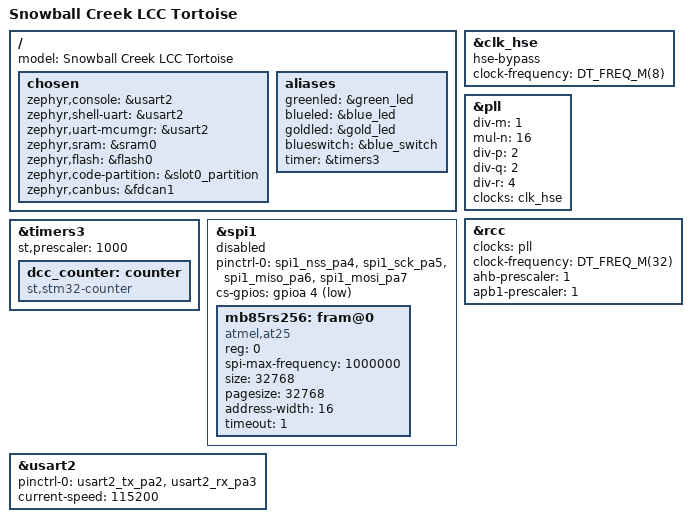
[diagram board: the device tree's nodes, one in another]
/dts-v1/;
#include <st/g0/stm32g0b1Xb.dtsi>
#include <st/g0/stm32g0b1c(b-c-e)tx-pinctrl.dtsi>

#include <zephyr/dt-bindings/input/input-event-codes.h>
#include <zephyr/dt-bindings/pinctrl/stm32-pinctrl.h>
#include <zephyr/dt-bindings/pinctrl/stm32-pinctrl-common.h>

/ {
	model = "Snowball Creek LCC Tortoise";

	chosen {
		zephyr,console = &usart2;
		zephyr,shell-uart = &usart2;
		zephyr,uart-mcumgr = &usart2;
		zephyr,sram = &sram0;
		zephyr,flash = &flash0;
		zephyr,code-partition = &slot0_partition;
		zephyr,canbus = &fdcan1;
	};


	aliases {
		greenled = &green_led;
		blueled = &blue_led;
		goldled = &gold_led;
		blueswitch = &blue_switch;
		timer = &timers3;
	};
};

/*
&clk_lsi {
	status = "okay";
};

&clk_hsi {
	status = "okay";
};

&clk_hsi48 {
	status = "okay";
	crs-usb-sof;
};
*/

&clk_hse {
	status = "okay";
	hse-bypass;
	clock-frequency = <DT_FREQ_M(8)>;
};

&pll {
	div-m = <1>;
	mul-n = <16>;
	div-p = <2>;
	div-q = <2>;
	div-r = <4>;
	clocks = <&clk_hse>;
	status = "okay";
};


&rcc {
	clocks = <&pll>;
	clock-frequency = <DT_FREQ_M(32)>;
	ahb-prescaler = <1>;
	apb1-prescaler = <1>;
};


/*
zephyr_udc0: &usb {
	pinctrl-0 = <&usb_dm_pa11 &usb_dp_pa12>;
	pinctrl-names = "default";
	status = "okay";
};
*/

/*
&usart1 {
	pinctrl-0 = <&usart1_tx_pc4 &usart1_rx_pc5>;
	pinctrl-names = "default";
	current-speed = <115200>;
	status = "disabled";
};
*/


/*
&rtc {
	clocks = <&rcc STM32_CLOCK_BUS_APB1 0x00000400>,
		 <&rcc STM32_SRC_LSI RTC_SEL(2)>;
	status = "okay";
};

&iwdg {
	status = "okay";
};
*/

&timers3 {
	st,prescaler = <1000>;
	status = "okay";
	dcc_counter: counter {
		compatible = "st,stm32-counter";
		status = "okay";
	};
};

/*
&timers15 {
	st,prescaler = <10000>;
	status = "okay";
	pwm15: pwm {
		status = "okay";
		pinctrl-0 = <&tim15_ch1_pb14>;
		pinctrl-names = "default";
	};
};

&i2c1 {
	pinctrl-0 = <&i2c1_scl_pb8 &i2c1_sda_pb9>;
	pinctrl-names = "default";
	status = "okay";
	clock-frequency = <I2C_BITRATE_FAST>;
};

&i2c2 {
	pinctrl-0 = <&i2c2_scl_pa11 &i2c2_sda_pa12>;
	pinctrl-names = "default";
	status = "okay";
	clock-frequency = <I2C_BITRATE_FAST>;
};
*/

&spi1 {
	pinctrl-0 = <&spi1_nss_pa4 &spi1_sck_pa5
		     &spi1_miso_pa6 &spi1_mosi_pa7>;
	pinctrl-names = "default";
	status = "disabled";

	cs-gpios = <&gpioa 4 GPIO_ACTIVE_LOW>;

	/* The MB85RS256 uses the same commands as the AT25 EEPROM */
	mb85rs256: fram@0 {
		compatible = "atmel,at25";
		reg = <0>;
		spi-max-frequency = <1000000>;
		size = <32768>;
		pagesize = <32768>;
		address-width = <16>;
		timeout = <1>;
	};
};

&usart2 {
	pinctrl-0 = <&usart2_tx_pa2 &usart2_rx_pa3>;
	pinctrl-names = "default";
	current-speed = <115200>;
	status = "okay";
};


